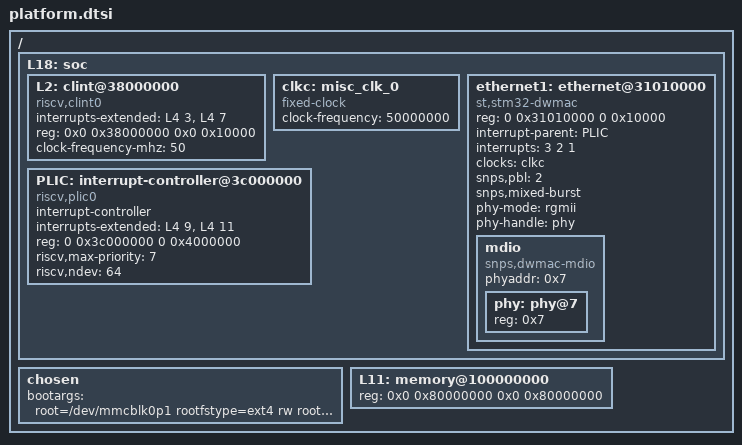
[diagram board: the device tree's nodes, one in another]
/dts-v1/;

/ {
    L18: soc {
        L2: clint@38000000 {
            compatible = "riscv,clint0";
            interrupts-extended = <&L4 3 &L4 7>;
            reg = <0x0 0x38000000 0x0 0x10000>;
            reg-names = "control";
            clock-frequency-mhz = <50>;
        };

        /*
        L14: serial@60000000 {
            compatible = "xilinx,uartlite";
            //interrupt-parent = <&L1>;
            interrupts = <3>;
            reg = <0x0 0x60000000 0x0 0x1000>;
            reg-names = "control";
        };

        sdhci: mmc {
            compatible = "nemu-sdhost";
            reg = <0x0 0x40002000 0x0 0x1000>;
        };
        */

        clkc: misc_clk_0 {
            #clock-cells = <0>;
            clock-frequency = <50000000>;
            compatible = "fixed-clock";
        };

        ethernet1: ethernet@31010000 {
            compatible = "st,stm32-dwmac", "snps,dwmac-3.50a";
            reg = <0 0x31010000 0 0x10000>;
            reg-names = "stmmaceth";
            interrupt-parent = <&PLIC>;
            interrupts = <3 2 1>;
            interrupt-names = "eth_lpi", "macirq", "eth_wake_irq";
            clock-names = "stmmaceth";
            clocks = <&clkc>;
            //st,syscon = <&syscfg 0x4>;
            snps,pbl = <2>;
            snps,mixed-burst;
            phy-mode = "rgmii";
            // stmmac driver can not find phy if add this node
            //
            phy-handle = <&phy>;
            mdio {
                #address-cells = <0x1>;
                #size-cells = <0x0>;
                phyaddr = <0x7>;
                compatible = "snps,dwmac-mdio";
                phy: phy@7 {
                    //phyaddr = <0x7>;
                    //compatible = "marvell,88e1116r";
                    //device_type = "ethernet-phy";
                    reg = <0x7>;
                };
            };
       };
/*
        ethernet: ethernet@31010000{
            #address-cells = <1>;
            #size-cells = <1>;
            compatible = "st,stm32-dwmac", "snps,dwmac-3.50a";
            reg-names = "stmmaceth";
            reg = <0 0x31010000 0 0x10000>;
            interrupt-names = "eth_wake_irq", "macirq", "eth_lpi";
            interrupt-parent = <&PLIC>;
            interrupts = <43 44 45>;
            clock-names = "stmmaceth";
            clocks = <&clkc>;
            snps,pbl = <2>;
            snps,mixed-burst;
            phy-mode = "rgmii";
        };
        */
/*
        sdhci2: sdhci@30050000 {
            compatible = "snps,dwcmshc-sdhci";
            reg = <0 0x30050000 0 0x10000>;
            interrupt-parent = <&PLIC>;
            interrupts = <55 56>;
            clocks = <&clkc>;
            clock-names = "core";
            sd-uhs-sdr12;
            disable-wp;
            bus-width = <4>;
        };
*/
        /*
        EXTINTR: external-interrupts {
            interrupt-parent = <&PLIC>;
            interrupts = <1 2 3 4 5>;
        };
        */

        PLIC: interrupt-controller@3c000000 {
            #interrupt-cells = <1>;
            compatible = "riscv,plic0";
            interrupt-controller;
            interrupts-extended = <&L4 9 &L4 11>;
            //reg = <0 0xc000000 0 0x4000000>;
            reg = <0 0x3c000000 0 0x4000000>;
            reg-names = "control";
            riscv,max-priority = <7>;
            riscv,ndev = <64>;
        };
    };

    chosen {
        bootargs = "root=/dev/mmcblk0p1 rootfstype=ext4 rw rootwait earlycon noinitrd";
    };

    L11: memory@100000000 {
        device_type = "memory";
        reg = <0x0 0x80000000 0x0 0x80000000>;
    };
};
